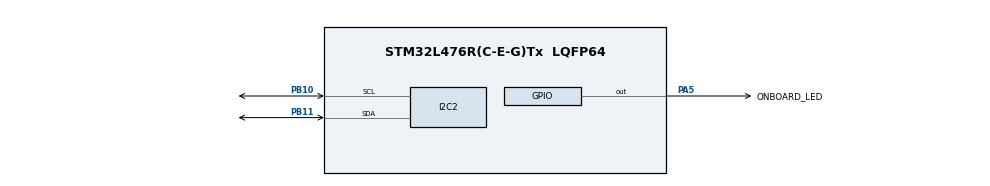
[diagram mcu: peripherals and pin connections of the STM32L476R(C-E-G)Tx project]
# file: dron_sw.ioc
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Mcu.Family=STM32L4
Mcu.Name=STM32L476R(C-E-G)Tx
Mcu.Package=LQFP64
NVIC.PriorityGroup=NVIC_PRIORITYGROUP_4
NVIC.TIM7_IRQn=true\:0\:0\:false\:false\:true\:true\:true
PA5.GPIO_Label=ONBOARD_LED
PA5.Signal=GPIO_Output
PB10.Mode=I2C
PB10.Signal=I2C2_SCL
PB11.Mode=I2C
PB11.Signal=I2C2_SDA
ProjectManager.HeapSize=0x200
ProjectManager.StackSize=0x400
ProjectManager.TargetToolchain=Makefile
RCC.HSE_VALUE=8000000
RCC.HSI_VALUE=16000000
RCC.LSE_VALUE=32768
RCC.MSI_VALUE=4000000
RCC.VCOOutputFreq_Value=32000000
TIM7.Period=25
TIM7.Prescaler=7999
VP_TIM7_VS_ClockSourceINT.Mode=Enable_Timer
board=custom

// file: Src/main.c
/* USER CODE BEGIN Header */
/**
  ******************************************************************************
  * @file           : main.c
  * @brief          : Main program body
  ******************************************************************************
  * @attention
  *
  * <h2><center>&copy; Copyright (c) 2020 STMicroelectronics.
  * All rights reserved.</center></h2>
  *
  * This software component is licensed by ST under BSD 3-Clause license,
  * the "License"; You may not use this file except in compliance with the
  * License. You may obtain a copy of the License at:
  *                        opensource.org/licenses/BSD-3-Clause
  *
  ******************************************************************************
  */
/* USER CODE END Header */

#include "main.h"
#include "i2c.h"
#include "tim.h"
#include "gpio.h"

/* USER CODE BEGIN Includes */
#include "imu.h"
/* USER CODE END Includes */

/* USER CODE BEGIN PV */
int16_t imu_acc_x_raw;
int16_t imu_acc_y_raw;
int16_t imu_acc_z_raw;

int16_t imu_mag_x_raw;
int16_t imu_mag_y_raw;
int16_t imu_mag_z_raw;
/* USER CODE END PV */

void SystemClock_Config(void);
/* USER CODE BEGIN PFP */
void HAL_TIM_PeriodElapsedCallback(TIM_HandleTypeDef *htim)
{
  imu_acc_x_raw = IMU_ReadAccXRaw();
  imu_acc_y_raw = IMU_ReadAccYRaw();
  imu_acc_z_raw = IMU_ReadAccZRaw();
  imu_mag_x_raw = IMU_ReadMagXRaw();
  imu_mag_y_raw = IMU_ReadMagYRaw();
  imu_mag_z_raw = IMU_ReadMagZRaw();
  if (HAL_GPIO_ReadPin(ONBOARD_LED_GPIO_Port, ONBOARD_LED_Pin) == GPIO_PIN_RESET)
    HAL_GPIO_WritePin(ONBOARD_LED_GPIO_Port, ONBOARD_LED_Pin, GPIO_PIN_SET);
  else
    HAL_GPIO_WritePin(ONBOARD_LED_GPIO_Port, ONBOARD_LED_Pin, GPIO_PIN_RESET);
}
/* USER CODE END PFP */

int main(void)
{

  /* MCU Configuration--------------------------------------------------------*/

  /* Reset of all peripherals, Initializes the Flash interface and the Systick. */
  HAL_Init();

  /* Configure the system clock */
  SystemClock_Config();

  /* Initialize all configured peripherals */
  MX_GPIO_Init();
  MX_I2C2_Init();
  MX_TIM7_Init();
  /* USER CODE BEGIN 2 */
  IMU_InitAcc();
  IMU_InitMag();

  HAL_NVIC_EnableIRQ(TIM7_IRQn);
  HAL_TIM_Base_Start_IT(&htim7);
  /* USER CODE END 2 */

  /* Infinite loop */
  while (1)
  {

  }
}

void SystemClock_Config(void)
{
  RCC_OscInitTypeDef RCC_OscInitStruct = {0};
  RCC_ClkInitTypeDef RCC_ClkInitStruct = {0};
  RCC_PeriphCLKInitTypeDef PeriphClkInit = {0};

  /** Initializes the CPU, AHB and APB busses clocks
  */
  RCC_OscInitStruct.OscillatorType = RCC_OSCILLATORTYPE_MSI;
  RCC_OscInitStruct.MSIState = RCC_MSI_ON;
  RCC_OscInitStruct.MSICalibrationValue = 0;
  RCC_OscInitStruct.MSIClockRange = RCC_MSIRANGE_6;
  RCC_OscInitStruct.PLL.PLLState = RCC_PLL_NONE;
  if (HAL_RCC_OscConfig(&RCC_OscInitStruct) != HAL_OK)
  {
    Error_Handler();
  }
  /** Initializes the CPU, AHB and APB busses clocks
  */
  RCC_ClkInitStruct.ClockType = RCC_CLOCKTYPE_HCLK|RCC_CLOCKTYPE_SYSCLK
                              |RCC_CLOCKTYPE_PCLK1|RCC_CLOCKTYPE_PCLK2;
  RCC_ClkInitStruct.SYSCLKSource = RCC_SYSCLKSOURCE_MSI;
  RCC_ClkInitStruct.AHBCLKDivider = RCC_SYSCLK_DIV1;
  RCC_ClkInitStruct.APB1CLKDivider = RCC_HCLK_DIV1;
  RCC_ClkInitStruct.APB2CLKDivider = RCC_HCLK_DIV1;

  if (HAL_RCC_ClockConfig(&RCC_ClkInitStruct, FLASH_LATENCY_0) != HAL_OK)
  {
    Error_Handler();
  }
  PeriphClkInit.PeriphClockSelection = RCC_PERIPHCLK_I2C2;
  PeriphClkInit.I2c2ClockSelection = RCC_I2C2CLKSOURCE_PCLK1;
  if (HAL_RCCEx_PeriphCLKConfig(&PeriphClkInit) != HAL_OK)
  {
    Error_Handler();
  }
  /** Configure the main internal regulator output voltage
  */
  if (HAL_PWREx_ControlVoltageScaling(PWR_REGULATOR_VOLTAGE_SCALE1) != HAL_OK)
  {
    Error_Handler();
  }
}

void Error_Handler(void)
{
}

/************************ (C) COPYRIGHT STMicroelectronics *****END OF FILE****/
